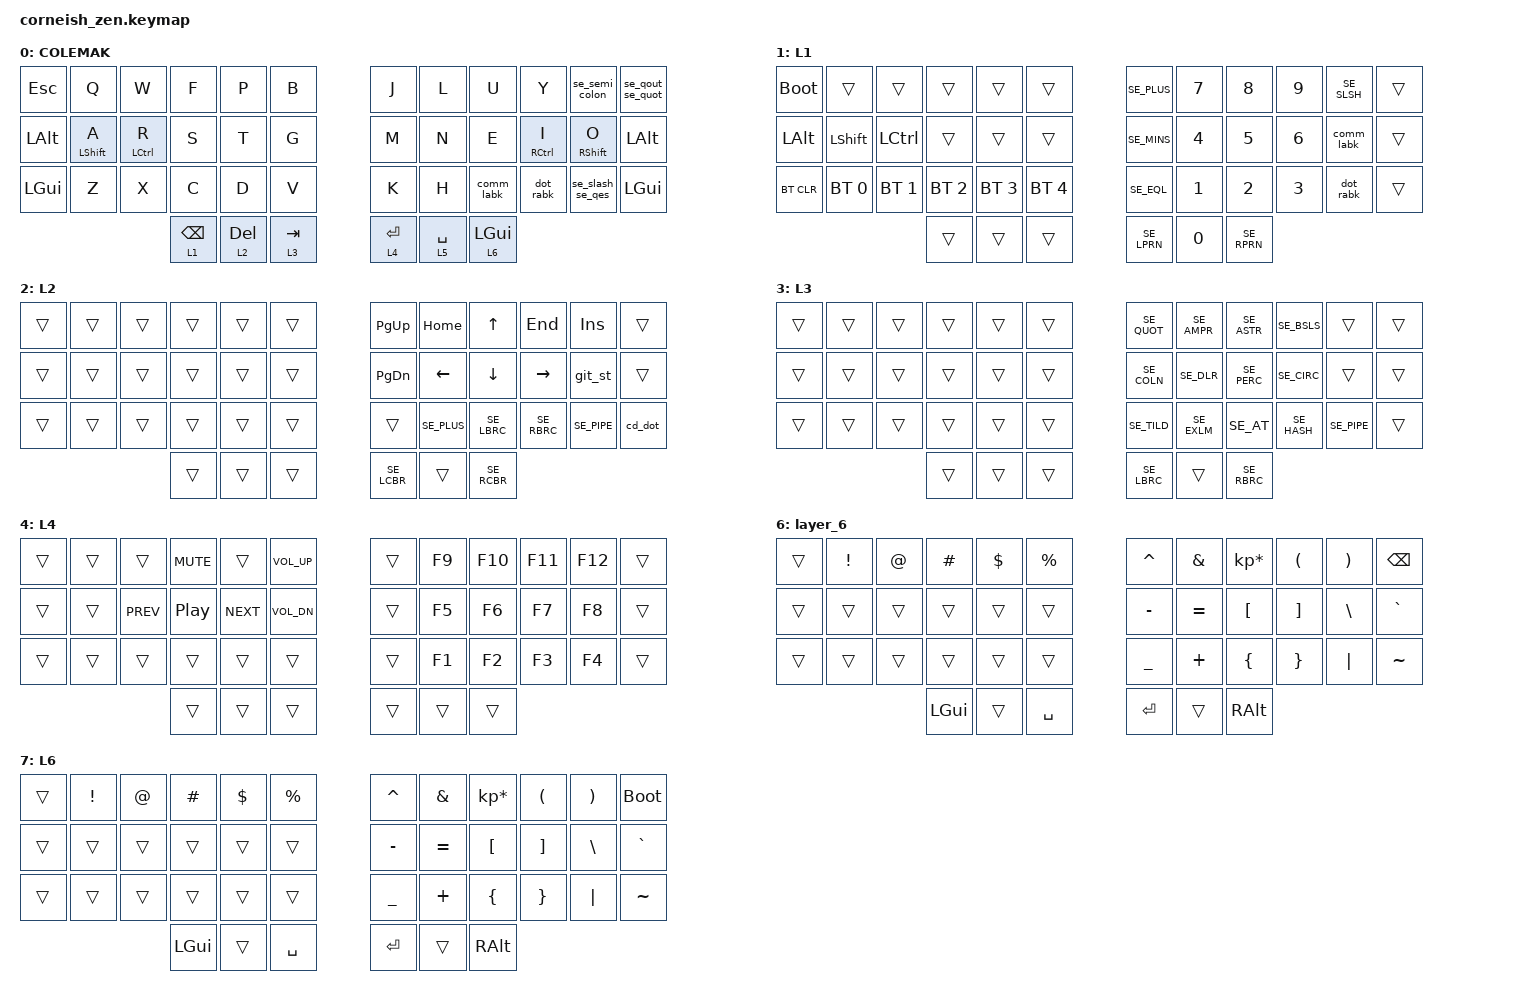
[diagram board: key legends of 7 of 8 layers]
/*
*
* Copyright (c) 2021 Darryl deHaan
* SPDX-License-Identifier: MIT
*
*/

#include <behaviors.dtsi>
#include <dt-bindings/zmk/keys.h>
#include <dt-bindings/zmk/bt.h>
#include "keys_se.h"



#define BASE   0
#define L1   1
#define L2   2
#define L3   3
#define L4   4
#define L5   5
#define L6   6

// / {
//     macros {
//         cd_dot: cd_dot {
//             label = "cd_dot_dot";
//             compatible = "zmk,behavior-macro";
//             wait-ms = <5>;
//             tap-ms = <5>;
//             #binding-cells = <0>;
//             bindings
//                 = <&macro_tap &kp C &kp D &kp DOT &kp DOT>
//                 , <&macro_tap &kp ENTER>
//                 ;
//         };

//     };
// };


// / {
//     macros {
//         zed_em_kay: zed_em_kay {
//             label = "ZM_zed_em_kay";
//             compatible = "zmk,behavior-macro";
//             #binding-cells = <0>;
//             bindings
//                 = <&macro_press &kp LSHFT>
//                 , <&macro_tap &kp Z &kp M &kp K>
//                 , <&macro_release &kp LSHFT>
//                 ;
//         };
//     };
// };



/{
 macros {
    git_st: git_st {
      label = "git_st_st";
      compatible = "zmk,behavior-macro";
      wait-ms = <0>;
       #binding-cells = <0>;
      bindings
      = <&kp G &kp I &kp T &kp SPACE &kp S &kp T &kp A &kp T>
      , <&kp U &kp S &kp ENTER>
      ;
    };
    cd_dot: cd_dot {
            label = "cd_dot_dot";
            compatible = "zmk,behavior-macro";
            wait-ms = <0>;
             #binding-cells = <0>;
            bindings
                = <&macro_tap &kp C &kp D &kp SPACE &kp SE_DOT &kp SE_DOT>
                , <&macro_tap &kp ENTER>
                ;
   };
 };
 };


/ {
  chosen {
    zmk,matrix_transform = &default_transform;
    //zmk,matrix_transform = &five_column_transform;
  };
};



/ {

        behaviors {
                #include "behaviors_mod_morph.dtsi"
        };

        keymap {
                compatible = "zmk,keymap";

                default_layer {
                        label = "COLEMAK";
// -----------------------------------------------------------------------------------------
// |  TAB |  Q  |  W  |  E  |  R  |  T  |   |  Y  |  U   |  I  |  O  |  P  | BKSP |
// | CTRL |  A  |  S  |  D  |  F  |  G  |   |  H  |  J   |  K  |  L  |  ;  |  '   |
// | SHFT |  Z  |  X  |  C  |  V  |  B  |   |  N  |  M   |  ,  |  .  |  /  | ESC  |
//                    | GUI | LWR | SPC |   | ENT | RSE  | ALT |


                        bindings = <
   &kp ESC   &kp Q &kp W &kp F &kp P &kp B                         &kp J &kp L  &kp U  &kp Y  &se_semi_colon &se_qout_se_quot
  &kp LALT  &mt LSHFT A &mt LCTRL R  &kp S &kp T &kp G             &kp M &kp N  &kp E  &mt RCTRL I &mt RSHFT O &kp LALT
  &kp LGUI   &kp Z &kp X &kp C &kp D &kp V                        &kp K &kp H  &comm_labk &dot_rabk &se_slash_se_qes &kp LGUI
                    	   &lt L1 BSPC  &lt L2 DEL &lt L3 TAB                              &lt L4 ENTER &lt L5 SPACE &lt L6 LGUI
                        >;
                };
                layer_0 {
                        label = "L1";
// -----------------------------------------------------------------------------------------
// |  TAB |  1  |  2  |  3  |  4  |  5  |   |  6  |  7  |  8  |  9  |  0  | BKSP |
// | BTCLR| BT1 | BT2 | BT3 | BT4 | BT5 |   | LFT | DWN |  UP | RGT |     |      |
// | SHFT |     |     |     |     |     |   |     |     |     |     |     |      |
//                    | GUI |     | SPC |   | ENT |     | ALT |
                        bindings = <
   &bootloader  &trans        &trans       &trans     &trans     &trans               &kp SE_PLUS  &kp N7   &kp N8 &kp N9    &kp SE_SLSH  &trans
   &kp LALT       &kp LSHFT    &kp LCTRL  &trans   &trans  &trans             &kp SE_MINS  &kp N4   &kp N5 &kp N6    &comm_labk  &trans
   &bt BT_CLR     &bt BT_SEL 0  &bt BT_SEL 1 &bt BT_SEL 2 &bt BT_SEL 3 &bt BT_SEL 4   &kp SE_EQL   &kp N1   &kp N2 &kp N3    &dot_rabk    &trans
                          	       &trans     &trans      &trans                  &kp SE_LPRN  &kp N0   &kp SE_RPRN
                        >;
                };

                layer_1 {
                        label = "L2";
// -----------------------------------------------------------------------------------------
// |  TAB |  !  |  @  |  #  |  $  |  %  |   |  ^  |  &  |  *  |  (  |  )  | BKSP |
// | CTRL |     |     |     |     |     |   |  -  |  =  |  [  |  ]  |  \  |  `   |
// | SHFT |     |     |     |     |     |   |  _  |  +  |  {  |  }  | "|" |  ~   |
//                    | GUI |     | SPC |   | ENT |     | ALT |
                        bindings = <
   &trans  &trans  &trans  &trans  &trans  &trans    &kp PG_UP &kp HOME  &kp UP_ARROW &kp END &kp INSERT &trans
   &trans  &trans  &trans  &trans  &trans  &trans    &kp PG_DN &kp LEFT_ARROW &kp DOWN_ARROW  &kp RIGHT_ARROW &git_st &trans
   &trans  &trans  &trans  &trans  &trans  &trans    &trans &kp SE_PLUS  &kp SE_LBRC &kp SE_RBRC &kp SE_PIPE &cd_dot
                    	   &trans  &trans  &trans    &kp SE_LCBR   &trans    &kp SE_RCBR
                        >;
                };



                layer_2 {
                        label = "L3";
// -----------------------------------------------------------------------------------------
// |  TAB |  !  |  @  |  #  |  $  |  %  |   |  ^  |  &  |  *  |  (  |  )  | BKSP |
// | CTRL |     |     |     |     |     |   |  -  |  =  |  [  |  ]  |  \  |  `   |
// | SHFT |     |     |     |     |     |   |  _  |  +  |  {  |  }  | "|" |  ~   |
//                    | GUI |     | SPC |   | ENT |     | ALT |
                        bindings = <
  &trans  &trans  &trans  &trans  &trans  &trans      &kp SE_QUOT  &kp SE_AMPR  &kp SE_ASTR  &kp SE_BSLS  &trans  &trans
  &trans  &trans  &trans  &trans  &trans  &trans      &kp SE_COLN  &kp SE_DLR  &kp SE_PERC  &kp SE_CIRC  &trans  &trans
  &trans  &trans  &trans  &trans  &trans  &trans      &kp SE_TILD  &kp SE_EXLM  &kp SE_AT  &kp SE_HASH  &kp SE_PIPE  &trans
                    	  &trans  &trans  &trans      &kp SE_LBRC  &trans   &kp SE_RBRC
                        >;
                };

                layer_3 {
                        label = "L4";
// -----------------------------------------------------------------------------------------
// |  TAB |  !  |  @  |  #  |  $  |  %  |   |  ^  |  &  |  *  |  (  |  )  | BKSP |
// | CTRL |     |     |     |     |     |   |  -  |  =  |  [  |  ]  |  \  |  `   |
// | SHFT |     |     |     |     |     |   |  _  |  +  |  {  |  }  | "|" |  ~   |
//                    | GUI |     | SPC |   | ENT |     | ALT |
                        bindings = <
   &trans  &trans  &trans &kp C_MUTE  &trans   &kp C_VOL_UP      &trans  &kp F9   &kp F10  &kp F11  &kp F12  &trans
   &trans  &trans  &kp C_PREV &kp C_PP   &kp C_NEXT   &kp C_VOL_DN      &trans  &kp F5   &kp F6   &kp F7   &kp F8   &trans
   &trans  &trans  &trans &trans   &trans   &trans      &trans  &kp F1   &kp F2   &kp F3   &kp F4   &trans
                          &trans   &trans   &trans      &trans  &trans   &trans
                        >;
                };

                layer_4 {
                        label = "L5";
// -----------------------------------------------------------------------------------------
// |  TAB |  !  |  @  |  #  |  $  |  %  |   |  ^  |  &  |  *  |  (  |  )  | BKSP |
// | CTRL |     |     |     |     |     |   |  -  |  =  |  [  |  ]  |  \  |  `   |
// | SHFT |     |     |     |     |     |   |  _  |  +  |  {  |  }  | "|" |  ~   |
//                    | GUI |     | SPC |   | ENT |     | ALT |
                        bindings = <
   &trans  &trans  &trans &trans   &trans   &trans         &trans   &trans   &trans   &trans   &trans   &trans
   &trans  &trans  &kp SE_ARNG &kp SE_ADIA   &kp SE_ODIA   &trans   &trans   &trans   &trans   &trans   &trans
   &trans  &trans  &trans &trans   &trans   &trans         &trans   &trans   &trans   &trans   &trans   &trans
                          &trans   &trans   &trans         &trans   &trans   &trans
                        >;
                };

                layer_5 {
                        label = "layer_6";
// -----------------------------------------------------------------------------------------
// |  TAB |  !  |  @  |  #  |  $  |  %  |   |  ^  |  &  |  *  |  (  |  )  | BKSP |
// | CTRL |     |     |     |     |     |   |  -  |  =  |  [  |  ]  |  \  |  `   |
// | SHFT |     |     |     |     |     |   |  _  |  +  |  {  |  }  | "|" |  ~   |
//                    | GUI |     | SPC |   | ENT |     | ALT |
                        bindings = <
   &trans &kp EXCL &kp AT &kp HASH &kp DLLR &kp PRCNT        &kp CARET &kp AMPS  &kp KP_MULTIPLY &kp LPAR &kp RPAR &kp BSPC
   &trans &trans   &trans &trans   &trans   &trans           &kp MINUS &kp EQUAL &kp LBKT        &kp RBKT &kp BSLH &kp GRAVE
   &trans &trans   &trans &trans   &trans   &trans           &kp UNDER &kp PLUS  &kp LBRC        &kp RBRC &kp PIPE &kp TILDE
                    	     &kp LGUI &trans   &kp SPACE     &kp RET   &trans    &kp RALT
                        >;
                };
                layer_6 {
                        label = "L6";
// -----------------------------------------------------------------------------------------
// |  TAB |  !  |  @  |  #  |  $  |  %  |   |  ^  |  &  |  *  |  (  |  )  | BKSP |
// | CTRL |     |     |     |     |     |   |  -  |  =  |  [  |  ]  |  \  |  `   |
// | SHFT |     |     |     |     |     |   |  _  |  +  |  {  |  }  | "|" |  ~   |
//                    | GUI |     | SPC |   | ENT |     | ALT |
                        bindings = <
   &trans &kp EXCL &kp AT &kp HASH &kp DLLR &kp PRCNT        &kp CARET &kp AMPS  &kp KP_MULTIPLY &kp LPAR &kp RPAR &bootloader
   &trans &trans   &trans &trans   &trans   &trans           &kp MINUS &kp EQUAL &kp LBKT        &kp RBKT &kp BSLH &kp GRAVE
   &trans &trans   &trans &trans   &trans   &trans           &kp UNDER &kp PLUS  &kp LBRC        &kp RBRC &kp PIPE &kp TILDE
                    	     &kp LGUI &trans   &kp SPACE     &kp RET   &trans    &kp RALT
                        >;
                };
        };
};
